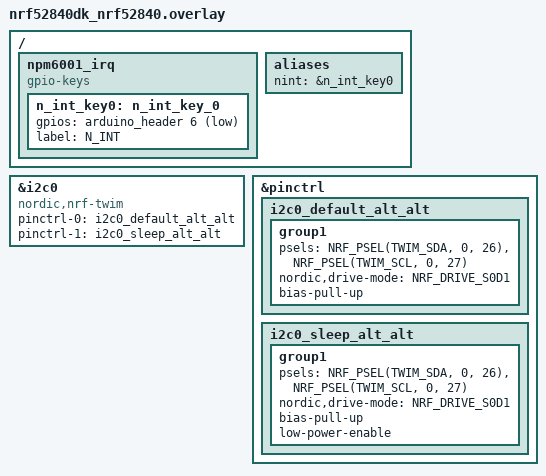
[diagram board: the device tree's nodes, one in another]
i2c0: &i2c0 {
	compatible = "nordic,nrf-twim";
	status = "okay";

	pinctrl-0 = <&i2c0_default_alt_alt>;
	pinctrl-1 = <&i2c0_sleep_alt_alt>;
	pinctrl-names = "default", "sleep";
};

&pinctrl {
	i2c0_default_alt_alt: i2c0_default_alt_alt {
		group1 {
			psels = <NRF_PSEL(TWIM_SDA, 0, 26)>,
				<NRF_PSEL(TWIM_SCL, 0, 27)>;
			nordic,drive-mode = <NRF_DRIVE_S0D1>;
			bias-pull-up;
		};
	};

	i2c0_sleep_alt_alt: i2c0_sleep_alt_alt {
		group1 {
			psels = <NRF_PSEL(TWIM_SDA, 0, 26)>,
				<NRF_PSEL(TWIM_SCL, 0, 27)>;
			nordic,drive-mode = <NRF_DRIVE_S0D1>;
			bias-pull-up;
			low-power-enable;
		};
	};
};

/ {
	npm6001_irq {
		compatible = "gpio-keys";
		n_int_key0: n_int_key_0 {
			gpios = <&arduino_header 6 (GPIO_PULL_UP | GPIO_ACTIVE_LOW)>;	/* D0 */
			label = "N_INT";
		};
	};

	aliases {
		nint = &n_int_key0;
	};
};
